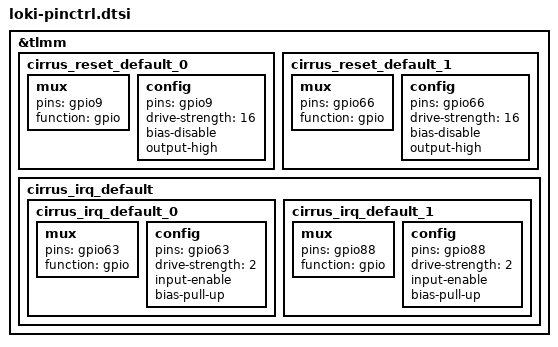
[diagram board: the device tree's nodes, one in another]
/*for loki pinctrl */

&tlmm {
	cirrus_reset_default_0: cirrus_reset_default_0 {
		mux {
			pins = "gpio9";
			function = "gpio";
		};

		config {
			pins = "gpio9";
			drive-strength = <16>;   /* 16 mA */
			bias-disable;
			output-high;
		};
	};

	cirrus_reset_default_1: cirrus_reset_default_1 {
		mux {
			pins = "gpio66";
			function = "gpio";
		};

		config {
			pins = "gpio66";
			drive-strength = <16>;   /* 16 mA */
			bias-disable;
			output-high;
		};
	};

	cirrus_irq_default {
		cirrus_irq_default_0: cirrus_irq_default_0 {
			mux {
					pins = "gpio63";
					function = "gpio";
			};
			config {
					pins = "gpio63";
					drive-strength = <2>;
					input-enable;
					bias-pull-up;
			};
		};
		cirrus_irq_default_1: cirrus_irq_default_1 {
			mux {
					pins = "gpio88";
					function = "gpio";
			};
			config {
					pins = "gpio88";
					drive-strength = <2>;
					input-enable;
					bias-pull-up;
			};
		};
	};
};
